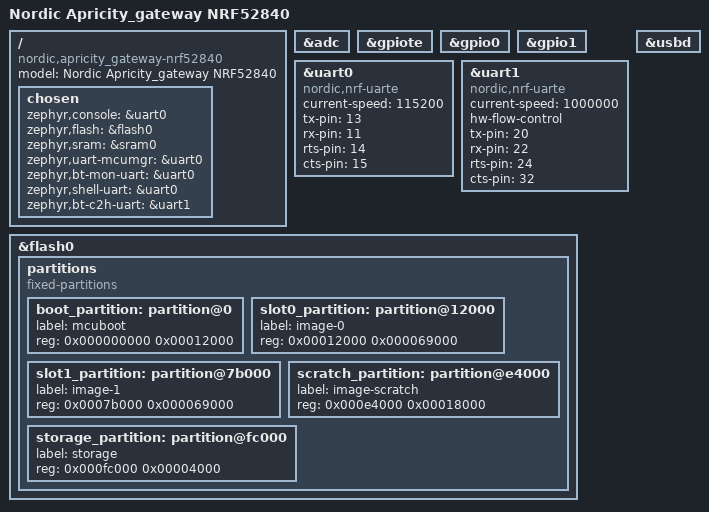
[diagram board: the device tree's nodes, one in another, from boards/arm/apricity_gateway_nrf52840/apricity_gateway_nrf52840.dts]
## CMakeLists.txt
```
#
# Copyright (c) 2018 Nordic Semiconductor
#
# SPDX-License-Identifier: LicenseRef-BSD-5-Clause-Nordic
#

cmake_minimum_required(VERSION 3.13.1)

list(APPEND mcuboot_OVERLAY_CONFIG
  "${CMAKE_CURRENT_SOURCE_DIR}/mcuboot_overlay-rsa.conf"
  )

set(mcuboot_CONF_FILE ${CMAKE_CURRENT_LIST_DIR}/mcuboot.conf)

#set(mcuboot_DTC_OVERLAY_FILE ${CMAKE_CURRENT_LIST_DIR}/apricity_gateway_nrf52840.overlay)

set(BOARD_ROOT ${CMAKE_CURRENT_LIST_DIR})
find_package(Zephyr REQUIRED HINTS $ENV{ZEPHYR_BASE})
project(lte-gateway-ble)

target_sources(app PRIVATE src/main.c)
target_sources(app PRIVATE src/usb_uart_bridge.c)
zephyr_include_directories(src)
```

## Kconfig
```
#
# Copyright (c) 2020 Nordic Semiconductor ASA
#
# SPDX-License-Identifier: LicenseRef-BSD-5-Clause-Nordic
#

menu "LTE Gateway BLE"
endmenu

menu "Zephyr Kernel"
source "Kconfig.zephyr"
endmenu

module = LTE_GATEWAY_BLE
module-str = LTE Gateway BLE
source "${ZEPHYR_BASE}/subsys/logging/Kconfig.template.log_config"
```

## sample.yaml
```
sample:
  description: USB-UART bridge with HCI UART sample
  name: USB-UART bridge HCI
tests:
  test_build:
    build_only: true
    build_on_all: true
    platform_whitelist: nrf52840_pca20035
    tags: ci_build
```

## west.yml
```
manifest:
  remotes:
    - name: nrfcloud
      url-base: https://github.com/nRFCloud
    - name: nordic
      url-base: https://github.com/nrfconnect
    - name: origin
      url-base: https://github.com/plskeggs
  projects:
    - name: sdk-nrf
      path: nrf
      remote: nordic
      revision: main
      import: true
  self:
    path: lte-gateway-ble
```

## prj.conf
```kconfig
#General
CONFIG_REBOOT=y
CONFIG_HEAP_MEM_POOL_SIZE=16384
CONFIG_GPIO=y
CONFIG_POLL=y
CONFIG_BOOTLOADER_MCUBOOT=y

 # USB
CONFIG_USB=y
CONFIG_USB_DEVICE_STACK=y
CONFIG_USB_DEVICE_MANUFACTURER="Apricity"
CONFIG_USB_DEVICE_PRODUCT="Apricity Gateway"
CONFIG_USB_DEVICE_VID=0x1915
CONFIG_USB_DEVICE_PID=0x520F
CONFIG_USB_DEVICE_SN="PCA20035 12PLACEHLDRS"
CONFIG_USB_COMPOSITE_DEVICE=y
CONFIG_USB_CDC_ACM=y
CONFIG_USB_CDC_ACM_RINGBUF_SIZE=4096
CONFIG_USB_CDC_ACM_DEVICE_COUNT=2
CONFIG_USB_CDC_ACM_LOG_LEVEL_INF=y

# Logging
CONFIG_LOG=y
CONFIG_LOG_MODE_IMMEDIATE=n
CONFIG_LOG_BACKEND_FORMAT_TIMESTAMP=n
CONFIG_LOG_DEFAULT_LEVEL=3
CONFIG_LTE_GATEWAY_BLE_LOG_LEVEL_INF=y
CONFIG_USE_SEGGER_RTT=y
CONFIG_SHELL_BACKEND_RTT=n
CONFIG_LOG_BACKEND_RTT=y
CONFIG_LOG_BACKEND_RTT_MODE_DROP=y
CONFIG_LOG_BACKEND_UART=n
CONFIG_SEGGER_RTT_BUFFER_SIZE_UP=256
CONFIG_LOG_PRINTK=y
CONFIG_LOG_PRINTK_MAX_STRING_LENGTH=256
CONFIG_LOG_BUFFER_SIZE=4096
CONFIG_LOG_BACKEND_RTT_MESSAGE_SIZE=256

 # UART
CONFIG_SERIAL=y
CONFIG_UART_INTERRUPT_DRIVEN=y
CONFIG_UART_LINE_CTRL=y
CONFIG_UART_ASYNC_API=n

#BT
CONFIG_BT=y
CONFIG_BT_WAIT_NOP=y
CONFIG_BT_HCI_RAW=y
CONFIG_BT_HCI_RAW_H4=y
CONFIG_BT_HCI_RAW_H4_ENABLE=y
CONFIG_BT_MAX_CONN=16
CONFIG_BT_TINYCRYPT_ECC=n
CONFIG_BT_CTLR_ASSERT_HANDLER=y
CONFIG_BT_HCI_TX_STACK_SIZE=2048
CONFIG_BT_HCI_TX_STACK_SIZE_WITH_PROMPT=y
CONFIG_BT_EXT_ADV=n

CONFIG_BT_DEBUG_LOG=n
CONFIG_BT_DEBUG_CONN=n
CONFIG_BT_DEBUG_HCI_CORE=n
CONFIG_BT_DEBUG_HCI_DRIVER=n
CONFIG_BT_LOG_LEVEL_INF=n
CONFIG_BT_HCI_VS_EXT=n
CONFIG_BT_HCI_VS=n

CONFIG_BT_LL_SOFTDEVICE=y
CONFIG_BT_LL_SW_SPLIT=y

#Reset pin
CONFIG_BOARD_APRICITY_GATEWAY_NRF52840_RESET=y
CONFIG_BOOTLOADER_MCUBOOT=y

# TODO: get this to work
#CONFIG_MCUBOOT_SERIAL=y
#CONFIG_BOOT_SERIAL_DETECT_PORT=0
#CONFIG_BOOT_SERIAL_DETECT_PIN=12

CONFIG_GPIO=y
CONFIG_MAIN_STACK_SIZE=2048
CONFIG_SYSTEM_WORKQUEUE_STACK_SIZE=2048

CONFIG_CLOCK_CONTROL_NRF_K32SRC_20PPM=y
```

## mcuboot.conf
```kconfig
# Note: much of this came from:
# bootloader/mcuboot/boot/zephyr/boards/thingy91_nrf52840.conf

# Disable Zephyr console
CONFIG_LOG=n
CONFIG_CONSOLE=n
CONFIG_CONSOLE_HANDLER=n
CONFIG_UART_CONSOLE=n

# The build won't fit on the partition allocated for it without size
# optimizations.
CONFIG_SIZE_OPTIMIZATIONS=y
CONFIG_PM_PARTITION_SIZE_MCUBOOT=0x12000

#Reset pin
CONFIG_BOARD_APRICITY_GATEWAY_NRF52840_RESET=y

# Serial
CONFIG_SERIAL=y
CONFIG_UART_NRFX=y
CONFIG_UART_INTERRUPT_DRIVEN=y
CONFIG_UART_LINE_CTRL=y

# MCUboot serial recovery
CONFIG_GPIO=y
CONFIG_MCUBOOT_SERIAL=y
CONFIG_BOOT_SERIAL_CDC_ACM=y
CONFIG_BOOT_SERIAL_DETECT_PORT="GPIO_0"
CONFIG_BOOT_SERIAL_DETECT_PIN=12
CONFIG_BOOT_SERIAL_DETECT_PIN_VAL=0

# Required by USB
CONFIG_MULTITHREADING=y

# USB
CONFIG_USB=y
CONFIG_USB_DEVICE_STACK=y
CONFIG_USB_DEVICE_PRODUCT="MCUBOOT"
CONFIG_USB_CDC_ACM=y
CONFIG_USB_COMPOSITE_DEVICE=y
CONFIG_USB_MASS_STORAGE=n
CONFIG_USB_DEVICE_MANUFACTURER="Nordic Semiconductor"
CONFIG_USB_DEVICE_VID=0x1915
CONFIG_USB_DEVICE_PID=0x520F

CONFIG_REBOOT=y
CONFIG_FLASH=y
CONFIG_MAIN_STACK_SIZE=10240
CONFIG_PARTITION_MANAGER_ENABLED=y
CONFIG_FPROTECT=y
CONFIG_HW_STACK_PROTECTION=y
```

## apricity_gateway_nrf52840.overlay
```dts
/* SPDX-License-Identifier: Apache-2.0 */

/ {
	chosen {
	};
};

/* This overlay is for MCUBOOT, used if needed to deviate from the
	application's device tree */
```

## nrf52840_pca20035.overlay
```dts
/* SPDX-License-Identifier: Apache-2.0 */

/ {
	chosen {
		zephyr,bt-c2h-uart=&uart1;
	};
};

// &uart1 {
// 	compatible = "nordic,nrf-uarte";
// 	current-speed = <1000000>;
// 	status = "okay";
//         tx-pin = <0x19>;
//         rx-pin = <0x20>;
//         rts-pin = <0x16>;
//         cts-pin = <0x13>;
// };


&uart0 {
	compatible = "nordic,nrf-uarte";
	current-speed = <0x1c200>;
	status = "okay";
	tx-pin = < 0x0d >;
	rx-pin = < 0x0b >;
	rts-pin = < 0x0e >;
	cts-pin = < 0x0f >;
};


&uart1 {
	compatible = "nordic,nrf-uarte";
	current-speed = <0xf4240>;
	status = "okay";
	tx-pin = < 0x14 >;
	rx-pin = < 0x16 >;
	rts-pin = < 0x18 >;
	cts-pin = < 0x20 >;
};
```

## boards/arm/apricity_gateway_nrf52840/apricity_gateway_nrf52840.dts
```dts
/*
 * Copyright (c) 2020 Nordic Semiconductor ASA
 *
 * SPDX-License-Identifier: LicenseRef-BSD-5-Clause-Nordic
 */

/dts-v1/;
#include <nordic/nrf52840_qiaa.dtsi>

/ {
	model = "Nordic Apricity_gateway NRF52840";
	compatible = "nordic,apricity_gateway-nrf52840";

	chosen {
		zephyr,console = &uart0;
		zephyr,flash = &flash0;
		zephyr,sram = &sram0;
		zephyr,uart-mcumgr = &uart0;
		zephyr,bt-mon-uart = &uart0;
		zephyr,shell-uart = &uart0;
		zephyr,bt-c2h-uart = &uart1;
	};
};

&adc {
	status = "okay";
};

&gpiote {
	status = "okay";
};

&gpio0 {
	status = "okay";
};

&gpio1 {
	status = "okay";
};

&uart0 {
	compatible = "nordic,nrf-uarte";
	current-speed = <115200>;
	status = "okay";
	tx-pin = < 13 >;
	rx-pin = < 11 >;
	rts-pin = < 14 >;
	cts-pin = < 15 >;
};

&uart1 {
	compatible = "nordic,nrf-uarte";
	current-speed = <1000000>;
	status = "okay";
	hw-flow-control;
	tx-pin = < 20 >;
	rx-pin = < 22 >;
	rts-pin = < 24 >;
	cts-pin = < 32 >;
};

&usbd {
	status = "okay";
};

&flash0 {
	partitions {
		compatible = "fixed-partitions";
		#address-cells = <1>;
		#size-cells = <1>;

		/* The size of this partition ensures that MCUBoot can be built
		 * with an RTT console, CDC ACM support, and w/o optimizations.
		 */
		boot_partition: partition@0 {
			label = "mcuboot";
			reg = <0x000000000 0x00012000>;
		};
		slot0_partition: partition@12000 {
			label = "image-0";
			reg = <0x00012000 0x000069000>;
		};
		slot1_partition: partition@7b000 {
			label = "image-1";
			reg = <0x0007b000 0x000069000>;
		};
		scratch_partition: partition@e4000 {
			label = "image-scratch";
			reg = <0x000e4000 0x00018000>;
		};
		storage_partition: partition@fc000 {
			label = "storage";
			reg = <0x000fc000 0x00004000>;
		};
	};
};
```

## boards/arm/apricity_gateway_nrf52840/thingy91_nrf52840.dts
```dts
/*
 * Copyright (c) 2019 Nordic Semiconductor ASA
 *
 * SPDX-License-Identifier: LicenseRef-BSD-5-Clause-Nordic
 */

/dts-v1/;
#include <nordic/nrf52840_qiaa.dtsi>

/ {
	model = "Nordic Thingy91 NRF52840";
	compatible = "nordic,thingy91-nrf52840";

	chosen {
		zephyr,console = &uart0;
		zephyr,flash = &flash0;
		zephyr,sram = &sram0;
		zephyr,uart-mcumgr = &uart0;
		zephyr,bt-mon-uart = &uart0;
		zephyr,shell-uart = &uart0;
	};
};

&adc {
	status = "okay";
};

&gpiote {
	status = "okay";
};

&gpio0 {
	status = "okay";
};

&gpio1 {
	status = "okay";
};

//&uart0 {
//	compatible = "nordic,nrf-uarte";
//	current-speed = <115200>;
//	status = "okay";
//	tx-pin = <15>;
//	rx-pin = <11>;
//	rts-pin = <21>;
//	cts-pin = <20>;
//};

&uart0 {
	compatible = "nordic,nrf-uarte";
	current-speed = <115200>;
	status = "okay";
	tx-pin = <28>;
	rx-pin = <30>;
};

&uart1 {
	current-speed = <1000000>;
	status = "okay";
	tx-pin = <25>;
	rx-pin = <32>;
	rts-pin = <22>;
	cts-pin = <19>;
};

&usbd {
	status = "okay";
};

&flash0 {
	partitions {
		compatible = "fixed-partitions";
		#address-cells = <1>;
		#size-cells = <1>;

		/* The size of this partition ensures that MCUBoot can be built
		 * with an RTT console, CDC ACM support, and w/o optimizations.
		 */
		boot_partition: partition@0 {
			label = "mcuboot";
			reg = <0x000000000 0x00012000>;
		};
		slot0_partition: partition@12000 {
			label = "image-0";
			reg = <0x00012000 0x000069000>;
		};
		slot1_partition: partition@7b000 {
			label = "image-1";
			reg = <0x0007b000 0x000069000>;
		};
		scratch_partition: partition@e4000 {
			label = "image-scratch";
			reg = <0x000e4000 0x00018000>;
		};
		storage_partition: partition@fc000 {
			label = "storage";
			reg = <0x000fc000 0x00004000>;
		};
	};
};
```

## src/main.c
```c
/*
 * Copyright (c) 2016-2021 Nordic Semiconductor ASA
 * Copyright (c) 2015-2016 Intel Corporation
 *
 * SPDX-License-Identifier: Apache-2.0
 */
#include <errno.h>
#include <stddef.h>
#include <stdio.h>
#include <string.h>

#include <zephyr.h>
#include <arch/cpu.h>
#include <sys/byteorder.h>
#include <logging/log.h>
#include <sys/util.h>

#include <device.h>
#include <init.h>
#include <drivers/uart.h>

#include <net/buf.h>
#include <bluetooth/bluetooth.h>
#include <bluetooth/l2cap.h>
#include <bluetooth/hci.h>
#include <bluetooth/buf.h>
#include <bluetooth/hci_raw.h>

#include <nrfx.h>
#include <hal/nrf_power.h>
#include <power/reboot.h>
#include <usb/usb_device.h>
#include <drivers/gpio.h>

#include "usb_uart_bridge.h"

LOG_MODULE_REGISTER(lte_gateway_ble, CONFIG_LTE_GATEWAY_BLE_LOG_LEVEL);

static const struct device *hci_uart_dev =
	DEVICE_DT_GET(DT_CHOSEN(zephyr_bt_c2h_uart));
static K_THREAD_STACK_DEFINE(tx_thread_stack, CONFIG_BT_HCI_TX_STACK_SIZE);
static struct k_thread tx_thread_data;
static K_FIFO_DEFINE(tx_queue);

/* RX in terms of bluetooth communication */
static K_FIFO_DEFINE(uart_tx_queue);

/* build for < rev3 hardware -- the BLE LED control used to be managed by
 * the 52840, but in newer boards is controlled by the 9160
 */
/* #define OLD_BOARD */

#if 0
/* HCI command buffers */
NET_BUF_POOL_FIXED_DEFINE(acl_tx_pool, TX_BUF_COUNT, BT_BUF_ACL_SIZE, NULL);
NET_BUF_POOL_FIXED_DEFINE(cmd_tx_pool, CONFIG_BT_HCI_CMD_COUNT, CMD_BUF_SIZE,
			  NULL);

/* #define DEBUG_UART_PINS */
#if defined(DEBUG_UART_PINS)
#define UART0 DT_NODELABEL(uart0)
#define UART0_TX DT_PROP(UART0, tx_pin)
#define UART0_RX DT_PROP(UART0, rx_pin)
#define UART0_RTS DT_PROP(UART0, rts_pin)
#define UART0_CTS DT_PROP(UART0, cts_pin)
#define UART0_SPEED DT_PROP(UART0, current_speed)
#define UART1 DT_NODELABEL(uart1)
#define UART1_TX DT_PROP(UART1, tx_pin)
#define UART1_RX DT_PROP(UART1, rx_pin)
#define UART1_RTS DT_PROP(UART1, rts_pin)
#define UART1_CTS DT_PROP(UART1, cts_pin)
#define UART1_SPEED DT_PROP(UART1, current_speed)
#endif

#if defined(CONFIG_BT_CTLR_TX_BUFFER_SIZE)
#define BT_L2CAP_MTU (CONFIG_BT_CTLR_TX_BUFFER_SIZE - BT_L2CAP_HDR_SIZE)
#else
#define BT_L2CAP_MTU 65 /* 64-byte public key + opcode */
#endif /* CONFIG_BT_CTLR */

/** Data size needed for ACL buffers */
#define BT_BUF_ACL_SIZE BT_L2CAP_BUF_SIZE(BT_L2CAP_MTU)

#if defined(CONFIG_BT_CTLR_TX_BUFFERS)
#define TX_BUF_COUNT CONFIG_BT_CTLR_TX_BUFFERS
#else
#define TX_BUF_COUNT 6
#endif
#define CMD_BUF_SIZE BT_BUF_RX_SIZE
#endif

#define H4_CMD 0x01
#define H4_ACL 0x02
#define H4_SCO 0x03
#define H4_EVT 0x04

/* Receiver states. */
#define ST_IDLE 0	/* Waiting for packet type. */
#define ST_HDR 1	/* Receiving packet header. */
#define ST_PAYLOAD 2	/* Receiving packet payload. */
#define ST_DISCARD 3	/* Dropping packet. */

/* Length of a discard/flush buffer.
 * This is sized to align with a BLE HCI packet:
 * 1 byte H:4 header + 32 bytes ACL/event data
 * Bigger values might overflow the stack since this is declared as a local
 * variable, smaller ones will force the caller to call into discard more
 * often.
 */
#define H4_DISCARD_LEN 33

#define H4_SEND_TIMEOUT 5000

static int h4_read(const struct device *uart, uint8_t *buf, size_t len)
{
	int rx = uart_fifo_read(uart, buf, len);

	LOG_DBG("read %d req %d", rx, len);

	return rx;
}

static bool valid_type(uint8_t type)
{
	return (type == H4_CMD) || (type == H4_ACL);
}

/* Function assumes that type is validated and only CMD or ACL will be used. */
static uint32_t get_len(const uint8_t *hdr_buf, uint8_t type)
{
	return (type == BT_BUF_CMD) ?
		((const struct bt_hci_cmd_hdr *)hdr_buf)->param_len :
		sys_le16_to_cpu(((const struct bt_hci_acl_hdr *)hdr_buf)->len);
}

/* Function assumes that type is validated and only CMD or ACL will be used. */
static int hdr_len(uint8_t type)
{
	return (type == H4_CMD) ?
		sizeof(struct bt_hci_cmd_hdr) : sizeof(struct bt_hci_acl_hdr);
}

static void rx_isr(void)
{
	static struct net_buf *buf;
	static int remaining;
	static uint8_t state;
	static uint8_t type;
	static uint8_t hdr_buf[MAX(sizeof(struct bt_hci_cmd_hdr),
			sizeof(struct bt_hci_acl_hdr))];
	int read;

	do {
		switch (state) {
		case ST_IDLE:
			/* Get packet type */
			read = h4_read(hci_uart_dev, &type, sizeof(type));
			/* since we read in loop until no data is in the fifo,
			 * it is possible that read = 0.
			 */
			if (read) {
				if (valid_type(type)) {
					/* Get expected header size and switch
					 * to receiving header.
					 */
					remaining = hdr_len(type);
					state = ST_HDR;
				} else {
					LOG_WRN("Unknown header %d", type);
				}
			}
			break;
		case ST_HDR:
			read = h4_read(hci_uart_dev,
				       &hdr_buf[hdr_len(type) - remaining],
				       remaining);
			remaining -= read;
			if (remaining == 0) {
				/* Header received. Allocate buffer and get
				 * payload length. If allocation fails leave
				 * interrupt. On failed allocation state machine
				 * is reset.
				 */
				buf = bt_buf_get_tx(BT_BUF_H4, K_NO_WAIT,
						    &type, sizeof(type));
				if (!buf) {
					state = ST_IDLE;
					return;
				}

				remaining = get_len(hdr_buf, type);

				net_buf_add_mem(buf, hdr_buf, hdr_len(type));
				if (remaining > net_buf_tailroom(buf)) {
					LOG_ERR("Not enough space in buffer");
					net_buf_unref(buf);
					state = ST_DISCARD;
				} else {
					state = ST_PAYLOAD;
				}

			}
			break;
		case ST_PAYLOAD:
			read = h4_read(hci_uart_dev, net_buf_tail(buf),
				       remaining);
			buf->len += read;
			remaining -= read;
			if (remaining == 0) {
				/* Packet received */
				LOG_DBG("putting RX packet in queue.");
				net_buf_put(&tx_queue, buf);
				state = ST_IDLE;
			}
			break;
		case ST_DISCARD:
		{
			uint8_t discard[H4_DISCARD_LEN];
			size_t to_read = MIN(remaining, sizeof(discard));

			read = h4_read(hci_uart_dev, discard, to_read);
			remaining -= read;
			if (remaining == 0) {
				state = ST_IDLE;
			}

			break;

		}
		default:
			read = 0;
			__ASSERT_NO_MSG(0);
			break;

		}
	} while (read);
}

static void tx_isr(void)
{
	static struct net_buf *buf;
	int len;

	if (!buf) {
		buf = net_buf_get(&uart_tx_queue, K_NO_WAIT);
		if (!buf) {
			uart_irq_tx_disable(hci_uart_dev);
			return;
		}
	}

	len = uart_fifo_fill(hci_uart_dev, buf->data, buf->len);
	net_buf_pull(buf, len);
	if (!buf->len) {
		net_buf_unref(buf);
		buf = NULL;
	}
}

static void bt_uart_isr(const struct device *unused, void *user_data)
{
	ARG_UNUSED(unused);
	ARG_UNUSED(user_data);

	if (!(uart_irq_rx_ready(hci_uart_dev) ||
	      uart_irq_tx_ready(hci_uart_dev))) {
		LOG_DBG("spurious interrupt");
	}

	if (uart_irq_tx_ready(hci_uart_dev)) {
		tx_isr();
	}

	if (uart_irq_rx_ready(hci_uart_dev)) {
		rx_isr();
	}
}

static void tx_thread(void *p1, void *p2, void *p3)
{
	while (1) {
		struct net_buf *buf;
		int err;

		/* Wait until a buffer is available */
		buf = net_buf_get(&tx_queue, K_FOREVER);
		/* Pass buffer to the stack */
		LOG_HEXDUMP_DBG(buf->data, buf->len, "tx_thread");
		LOG_DBG("net_buf_get() returned len %d", buf->len);
		err = bt_send(buf);
		if (err) {
			LOG_ERR("Unable to send (err %d)", err);
			net_buf_unref(buf);
		}

		/* Give other threads a chance to run if tx_queue keeps getting
		 * new data all the time.
		 */
		k_yield();
	}
}

static int h4_send(struct net_buf *buf)
{
	LOG_DBG("buf %p type %u len %u", buf, bt_buf_get_type(buf),
		    buf->len);

	net_buf_put(&uart_tx_queue, buf);
	uart_irq_tx_enable(hci_uart_dev);

	return 0;
}

#if defined(CONFIG_BT_CTLR_ASSERT_HANDLER)
void bt_ctlr_assert_handle(char *file, uint32_t line)
{
	uint32_t len = 0U, pos = 0U;

	/* Disable interrupts, this is unrecoverable */
	(void)irq_lock();

	uart_irq_rx_disable(hci_uart_dev);
	uart_irq_tx_disable(hci_uart_dev);

	if (file) {
		while (file[len] != '\0') {
			if (file[len] == '/') {
				pos = len + 1;
			}
			len++;
		}
		file += pos;
		len -= pos;
	}

	uart_poll_out(hci_uart_dev, H4_EVT);
	/* Vendor-Specific debug event */
	uart_poll_out(hci_uart_dev, 0xff);
	/* 0xAA + strlen + \0 + 32-bit line number */
	uart_poll_out(hci_uart_dev, 1 + len + 1 + 4);
	uart_poll_out(hci_uart_dev, 0xAA);

	if (len) {
		while (*file != '\0') {
			uart_poll_out(hci_uart_dev, *file);
			file++;
		}
		uart_poll_out(hci_uart_dev, 0x00);
	}

	uart_poll_out(hci_uart_dev, line >> 0 & 0xff);
	uart_poll_out(hci_uart_dev, line >> 8 & 0xff);
	uart_poll_out(hci_uart_dev, line >> 16 & 0xff);
	uart_poll_out(hci_uart_dev, line >> 24 & 0xff);

	while (1) {
	}
}
#endif /* CONFIG_BT_CTLR_ASSERT_HANDLER */

static int hci_uart_init(const struct device *unused)
{
	LOG_DBG("init hci uart");

	if (!device_is_ready(hci_uart_dev)) {
		LOG_ERR("HCI UART %s is not ready", hci_uart_dev->name);
		return -EINVAL;
	}

	uart_irq_rx_disable(hci_uart_dev);
	uart_irq_tx_disable(hci_uart_dev);

	uart_irq_callback_set(hci_uart_dev, bt_uart_isr);

	uart_irq_rx_enable(hci_uart_dev);

	return 0;
}

SYS_DEVICE_DEFINE("hci_uart", hci_uart_init, NULL,
		  APPLICATION, CONFIG_KERNEL_INIT_PRIORITY_DEVICE);

#if defined(OLD_BOARD)
void set_leds(bool red, bool green, bool blue)
{
	const struct device *port;
	int red_pin = 26;
	int green_pin = 4;
	int blue_pin = 6;
	int err;

	port = device_get_binding(DT_LABEL(DT_NODELABEL(gpio0)));
	if (!port) {
		LOG_INF("GPIO0 device not found!");
	} else {
		err = gpio_pin_configure(port, red_pin,
			red ? GPIO_OUTPUT_LOW : GPIO_OUTPUT_HIGH);
		if (err) {
			LOG_INF("Pin %d error %d", red_pin, err);
		}
		err = gpio_pin_configure(port, green_pin,
			green ? GPIO_OUTPUT_LOW : GPIO_OUTPUT_HIGH);
		if (err) {
			LOG_INF("Pin %d error %d", green_pin, err);
		}
		err = gpio_pin_configure(port, blue_pin,
			blue ? GPIO_OUTPUT_LOW : GPIO_OUTPUT_HIGH);
		if (err) {
			LOG_INF("Pin %d error %d", blue_pin, err);
		}
	}
}
#endif

void output_string(int id, char *str)
{
	struct serial_dev *sd = &devs[id];
	struct uart_data *rx = k_malloc(sizeof(struct uart_data));

	if (rx) {
		memset(rx, 0, sizeof(rx));
		rx->len = strlen(str);
		strcpy(rx->buffer, str);
		k_fifo_put(sd->fifo, rx);
		k_sem_give(&sd->sem);
	}
}

#define DBG(x) output_string(0, x)

static void log_uart_pins(void)
{
#if defined(DEBUG_UART_PINS)
	struct uart_config config;
	struct device *uart_0_dev = device_get_binding("UART_0");
	struct device *uart_1_dev = device_get_binding("UART_1");

	LOG_INF("UART0 tx:%d, rx:%d, rts:%d, cts:%d, speed:%d",
		UART0_TX, UART0_RX, UART0_RTS, UART0_CTS, UART0_SPEED);
	LOG_INF("UART1 tx:%d, rx:%d, rts:%d, cts:%d, speed:%d",
		UART1_TX, UART1_RX, UART1_RTS, UART1_CTS, UART1_SPEED);
	k_sleep(K_MSEC(50));

	uart_config_get(uart_0_dev, &config);
	LOG_INF("UART0 speed:%u, flow:%d", config.baudrate,
		config.flow_ctrl);
	k_sleep(K_MSEC(50));

	uart_config_get(uart_1_dev, &config);
	LOG_INF("UART1 speed:%u, flow:%d", config.baudrate,
		config.flow_ctrl);

	LOG_INF("Reset pin:%d",
		CONFIG_BOARD_APRICITY_GATEWAY_NRF52840_RESET_PIN);
#endif
}

extern bool ignore_reset;
void main(void)
{
	ignore_reset = false;

	/* incoming events and data from the controller */
	static K_FIFO_DEFINE(rx_queue);
	int err;
	int ret;
	struct serial_dev *usb_0_sd = &devs[0];
	struct serial_dev *uart_0_sd = &devs[1];
	const struct device *usb_0_dev;
	const struct device *uart_0_dev;

#if defined(OLD_BOARD)
	set_leds(true, false, false);
#endif
	__ASSERT(hci_uart_dev, "UART device is NULL");

	/* Enable the raw interface, this will in turn open the HCI driver */
	bt_enable_raw(&rx_queue);
#if defined(OLD_BOARD)
	set_leds(false, true, false);
#endif
	LOG_INF("LTE Gateway BLE started");
	log_uart_pins();

	if (IS_ENABLED(CONFIG_BT_WAIT_NOP)) {
		/* Issue a Command Complete with NOP */
		int i;

		const struct {
			const uint8_t h4;
			const struct bt_hci_evt_hdr hdr;
			const struct bt_hci_evt_cmd_complete cc;
		} __packed cc_evt = {
			.h4 = H4_EVT,
			.hdr = {
				.evt = BT_HCI_EVT_CMD_COMPLETE,
				.len = sizeof(struct bt_hci_evt_cmd_complete),
			},
			.cc = {
				.ncmd = 1,
				.opcode = sys_cpu_to_le16(BT_OP_NOP),
			},
		};

		LOG_INF("Sending HCI Cmd Complete w/ NOP");
		for (i = 0; i < sizeof(cc_evt); i++) {
			uart_poll_out(hci_uart_dev,
				      *(((const uint8_t *)&cc_evt)+i));
		}
	}

	/* Spawn the TX thread and start feeding commands and data to the
	 * controller
	 */
	k_thread_create(&tx_thread_data, tx_thread_stack,
			K_THREAD_STACK_SIZEOF(tx_thread_stack), tx_thread,
			NULL, NULL, NULL, K_PRIO_COOP(7), 0, K_NO_WAIT);
	k_thread_name_set(&tx_thread_data, "HCI uart TX");

	usb_0_dev = device_get_binding("CDC_ACM_0");
	if (!usb_0_dev) {
		LOG_INF("CDC ACM device not found");
		return;
	}

	uart_0_dev = device_get_binding("UART_0");
	if (!uart_0_dev) {
		LOG_INF("UART 0 init failed");
	}

	usb_0_sd->num = -1;
	usb_0_sd->dev = usb_0_dev;
	usb_0_sd->fifo = &usb_0_tx_fifo;
	usb_0_sd->peer = uart_0_sd;

	uart_0_sd->num = 0;
	uart_0_sd->dev = uart_0_dev;
	uart_0_sd->fifo = &uart_0_tx_fifo;
	uart_0_sd->peer = usb_0_sd;

	k_sem_init(&usb_0_sd->sem, 0, 1);
	k_sem_init(&uart_0_sd->sem, 0, 1);

	uart_bridge_init(usb_0_sd, uart_0_sd);

	uart_irq_callback_user_data_set(usb_0_dev, uart_interrupt_handler,
		usb_0_sd);
	uart_irq_callback_user_data_set(uart_0_dev, uart_interrupt_handler,
		uart_0_sd);

	ret = usb_enable(NULL);
	if (ret != 0) {
		LOG_INF("Failed to enable USB");
		return;
	}

	uart_irq_rx_enable(usb_0_dev);
	uart_irq_rx_enable(uart_0_dev);

	struct k_poll_event events[2] = {
		K_POLL_EVENT_STATIC_INITIALIZER(K_POLL_TYPE_SEM_AVAILABLE,
						K_POLL_MODE_NOTIFY_ONLY,
						&usb_0_sd->sem, 0),
		K_POLL_EVENT_STATIC_INITIALIZER(K_POLL_TYPE_SEM_AVAILABLE,
						K_POLL_MODE_NOTIFY_ONLY,
						&uart_0_sd->sem, 0),
	};

	LOG_INF("Entering loop");
#if defined(OLD_BOARD)
	set_leds(false, false, true);
#endif

	while (1) {
		struct net_buf *buf;

		buf = net_buf_get(&rx_queue, K_NO_WAIT);
		if (buf) {
			err = h4_send(buf);
			if (err) {
				LOG_ERR("Failed to send");
#if defined(OLD_BOARD)
				set_leds(true, false, false);
#endif
			} else {
#if defined(OLD_BOARD)
				set_leds(false, true, false);
#endif
			}
		}
		ret = k_poll(events, ARRAY_SIZE(events), K_NO_WAIT);
		if (ret != 0) {
			k_sleep(K_MSEC(1));
#if defined(OLD_BOARD)
			set_leds(false, false, true);
#endif
			continue;
		}

		if (events[0].state == K_POLL_TYPE_SEM_AVAILABLE) {
			events[0].state = K_POLL_STATE_NOT_READY;
			k_sem_take(&usb_0_sd->sem, K_NO_WAIT);
#if defined(OLD_BOARD)
			set_leds(false, true, true);
#endif
			LOG_DBG("en usb0 tx");
			uart_irq_tx_enable(usb_0_dev);
		} else if (events[1].state == K_POLL_TYPE_SEM_AVAILABLE) {
			events[1].state = K_POLL_STATE_NOT_READY;
			k_sem_take(&uart_0_sd->sem, K_NO_WAIT);
#if defined(OLD_BOARD)
			set_leds(true, false, true);
#endif
			LOG_DBG("en uart0 tx");
			uart_irq_tx_enable(uart_0_dev);
		}
	}
}
```

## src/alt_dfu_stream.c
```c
#include "alt_dfu_stream.h"

#include "tk_mqtt_dfu.h"

#include "cJSON.h"

#include <kernel.h>

#include <stdbool.h>
#include <stdio.h>
#include <stdlib.h>
#include <string.h>


/* Copied from dfu_target_peripheral.h */
#define DFU_PACKET_MAGIC_LEN (8u)
#define DFU_MAGIC_STRING "XoPU24Tk"

#define DFU_PACKET_HEADER_LEN (DFU_PACKET_MAGIC_LEN + 6u)
#define DFU_HEADER_FMT (DFU_MAGIC_STRING " %04d %s\n")

#define DFU_MAX_CHUNK_LEN (128u)

#define DFU_JSON_MAX_B64_DATA_LEN (4u * (DFU_MAX_CHUNK_LEN / 3u) + 3u)
#define DFU_JSON_MAX_LEN (DFU_JSON_MAX_B64_DATA_LEN + 100u)

#define DFU_PACKET_MAX_BUFFER_LEN \
	(DFU_PACKET_HEADER_LEN + DFU_JSON_MAX_LEN + 2u)

#define TX_PACKET_MAX_BUFFER_LEN (200u)

#define CMD_START_DFU   (7u)
#define CMD_DFU_DATA    (9u)


/* Local buffers */
K_MUTEX_DEFINE(rx_buffer_mutex);
static uint8_t rx_buffer[DFU_PACKET_MAX_BUFFER_LEN];
static volatile size_t rx_buffer_len = 0;

static char resp_str[(TX_PACKET_MAX_BUFFER_LEN - DFU_PACKET_HEADER_LEN) + 1];
static uint8_t tx_buffer[TX_PACKET_MAX_BUFFER_LEN];
static size_t tx_buffer_len = 0;


static inline void trim_rx_buffer(size_t idx)
{
	k_mutex_lock(&rx_buffer_mutex, K_FOREVER);

	if (idx >= rx_buffer_len) {
		rx_buffer_len = 0u;
	} else if (idx > 0) {
		rx_buffer_len = rx_buffer_len - idx;
		memmove(rx_buffer, rx_buffer+idx, rx_buffer_len);
	}

	k_mutex_unlock(&rx_buffer_mutex);
}

static void build_response_pkt(cJSON * response)
{
	int olen = 0;

	if ((NULL != response) &&
		cJSON_PrintPreallocated(response, resp_str, sizeof(resp_str), false)) {
		size_t json_len = strlen(resp_str);
		olen = snprintf((char *) tx_buffer, sizeof(tx_buffer),
						DFU_HEADER_FMT, json_len, resp_str);
	} else {
		int olen = snprintf((char *) tx_buffer, sizeof(tx_buffer),
							DFU_HEADER_FMT, 2, "{}");
	}

	if (olen < sizeof(tx_buffer)) {
		tx_buffer_len = olen;
	} else {
		tx_buffer_len = 0;
	}
}

static void process_rx_pkt(const char *json_str)
{
	cJSON *obj = cJSON_Parse(json_str);
	cJSON *response = NULL;

	if (NULL != obj) {
		cJSON * cmd_obj = cJSON_GetObjectItem(obj, "cmd");
		if ((NULL != cmd_obj) && cJSON_IsNumber(cmd_obj)) {
			switch(cmd_obj->valueint)
			{
			case CMD_START_DFU:
				response = TK_MQTT_DFU_START_M(obj);
				break;
			case CMD_DFU_DATA:
				response = TK_MQTT_DFU_DATA_M(obj);
				break;
			default:
				break;
			}
		}
	}

	build_response_pkt(response);
	cJSON_Delete(response);
	cJSON_Delete(obj);
}

static void process_rx_buffer(void)
{
	do
	{
		if (rx_buffer_len < DFU_PACKET_HEADER_LEN) {
			/* Not enough data to process*/
			break;
		}

		/* Trim off any garbage in the buffer */
		size_t trim_idx = 0;
		for (; trim_idx < (rx_buffer_len - DFU_PACKET_MAGIC_LEN); ++trim_idx) {
			if (DFU_MAGIC_STRING[0] == rx_buffer[trim_idx]) {
				break;
			}
		}
		if (trim_idx > 0) {
			trim_rx_buffer(trim_idx);
			continue;
		}

		if (0 != memcmp(rx_buffer, DFU_MAGIC_STRING, DFU_PACKET_MAGIC_LEN)) {
			/* Magic string does not match, remove the garbage */
			trim_rx_buffer(1);
			continue;
		}

		/* Grab the length field */
		size_t json_len = 0u;
		{
			char len_str[5];
			memcpy(len_str, &rx_buffer[DFU_PACKET_MAGIC_LEN + 1], 4);
			len_str[4] = '\0';

			long int raw_len = strtol(len_str, NULL, 10);
			if ((0 == raw_len) || (raw_len > DFU_JSON_MAX_LEN)) {
				/* Invalid length field, thrown the mysteriously matching magic
				   string */
				trim_rx_buffer(DFU_PACKET_MAGIC_LEN);
				continue;
			}
			json_len = (size_t) raw_len;
		}

		size_t pkt_len = json_len + DFU_PACKET_HEADER_LEN;
		if (rx_buffer_len < pkt_len) {
			/* Not enough bytes to extract the JSON data */
			break;
		}

		const char *json_str = (const char *) &rx_buffer[DFU_PACKET_HEADER_LEN];
		rx_buffer[pkt_len] = '\0';

		/* Complete packet has been received, process it. We will break
		   from the loop here so that a response message can be sent back */
		process_rx_pkt(json_str);
		trim_rx_buffer(pkt_len);
	} while(0);
}

void alt_dfu_process(void)
{
	if (tx_buffer_len == 0) {
		/* Only process data if there isn't an outgoing packet */
		process_rx_buffer();
	}
}

void alt_dfu_receive(const uint8_t *data, size_t len)
{
	k_mutex_lock(&rx_buffer_mutex, K_FOREVER);

	size_t to_copy = len;
	size_t bytes_free = sizeof(rx_buffer) - rx_buffer_len;
	if (bytes_free < len)
		to_copy = bytes_free;

	memcpy(&rx_buffer[rx_buffer_len], data, to_copy);
	rx_buffer_len += to_copy;

	k_mutex_unlock(&rx_buffer_mutex);
}

bool alt_dfu_is_tx_pending(void)
{
	return (tx_buffer_len > 0);
}

const uint8_t *alt_dfu_get_pending_tx(size_t *len)
{
	if (tx_buffer_len > 0) {
		*len = tx_buffer_len;
		tx_buffer_len = 0;
		return tx_buffer;
	} else {
		*len = 0;
		return NULL;
	}
}
```

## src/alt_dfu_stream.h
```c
#ifndef ALT_DFU_STREAM_H_
#define ALT_DFU_STREAM_H_

#include <stdbool.h>
#include <stdint.h>
#include <stddef.h>

void alt_dfu_process(void);

void alt_dfu_receive(const uint8_t *data, size_t len);

bool alt_dfu_is_tx_pending(void);

const uint8_t *alt_dfu_get_pending_tx(size_t *len);

#endif /* ALT_DFU_STREAM_H_ */
```

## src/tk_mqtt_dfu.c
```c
#include "tk_mqtt_dfu.h"

#include "tk_shutdown.h"

#include <cJSON.h>
#include <cJSON_os.h>

#include <zephyr.h>
#include <logging/log.h>

#include <dfu/flash_img.h>
#include <dfu/mcuboot.h>
#include <power/reboot.h>
#include <sys/base64.h>

#include <string.h>

LOG_MODULE_REGISTER(alt_dfu_stream, CONFIG_LTE_GATEWAY_BLE_LOG_LEVEL);

#define MAX_DATA_LENGTH         2048            // 2048*4/3 = size of base64 string of 2048

#define FILE_SIZE_NAME          "file_size"
#define MAX_CHUNK_NAME          "max_chunk_size"
#define VERSION_NAME            "version"
#define TOTAL_MSQ_COUNT_NAME    "total_msg_count"
#define MSG_ID_NAME             "msg_id"
#define CHUNK_NAME              "chunk_size"
#define DATA_NAME               "data"
#define DEV_ID_NAME             "devID"

static int file_size = 0;
static int max_chunk_size = 0;
static int final_msg = 0;
static int current_msg = 0;

static struct	flash_img_context flash_img;


static cJSON * tk_mqtt_create_request(void);


// static char version[] = "00.00.00" // Not currently using version

// Process a message to start a DFU process
/*
{
    "cmd":CMD_START_DFU,
    "file_size":250000,     // bytes
    "max_chunk_size":2048,  // bytes
    "version":"1.0.0",      // string
    "total_msg_count":245   // Number of messages expected
}
*/
cJSON * tk_mqtt_dfu_start(cJSON *msg){

    int err = flash_img_init(&flash_img);

	if (err != 0) {
		LOG_ERR("flash_img_init error %d", err);
		return NULL;
	}

    current_msg = 0;

    cJSON *fs = cJSON_GetObjectItem(msg,FILE_SIZE_NAME);
    if(fs == NULL)
    {
        LOG_ERR("Missing File Size");
        return NULL;
    }
    file_size = fs->valueint;

    cJSON *mcs = cJSON_GetObjectItem(msg,MAX_CHUNK_NAME);
    if(mcs == NULL)
    {
        LOG_ERR("Missing Chunk Size");
        return NULL;
    }
    max_chunk_size = mcs->valueint;

    cJSON *tmc =  cJSON_GetObjectItem(msg,TOTAL_MSQ_COUNT_NAME);
    if(tmc == NULL)
    {
        LOG_ERR("Missing Total Message Count");
        return NULL;
    }
    final_msg = tmc->valueint - 1;

    // Send request for first message
    return tk_mqtt_create_request();
}


// Process a dfu data message
/*
{
    "cmd":CMD_DFU_DATA,
    "msg_id":145,               // ID of the message
    "chunk_size":2048,          // bytes
    "data":"BASE64ENCODEDDATA"  //String
}
*/
static uint16_t msg_id = 0;
static size_t chunk_size = 0;
static uint8_t data[MAX_DATA_LENGTH];
static size_t olen;
cJSON * tk_mqtt_dfu_data(cJSON *msg){

    int err;

    cJSON *mi = cJSON_GetObjectItem(msg, MSG_ID_NAME);
    msg_id = mi->valueint;

    LOG_INF("msg_id %d, current_id %d", msg_id, current_msg);
    if(msg_id != current_msg)
    {
        return NULL;
    }
    else if ((current_msg-msg_id) == 1)
    {
        //If we received a previous message again, then the central server probably failed to get this
        //request, so send it again.
        return tk_mqtt_create_request();
    }

    cJSON *cs = cJSON_GetObjectItem(msg, CHUNK_NAME);
    chunk_size = cs->valueint;

    // Get data string and decode to uint8_t
    cJSON *d = cJSON_GetObjectItem(msg, DATA_NAME);
    base64_decode(data,chunk_size,&olen,d->valuestring,strlen(d->valuestring));

    LOG_INF("Chunk size:%d, Olen:%d",chunk_size,olen);

    // Write to flash
    err = flash_img_buffered_write(&flash_img,data,olen, false);
    if (err != 0) {
        LOG_ERR("flash_img_buffered_write error %d", err);
        return NULL;
    }

    // If last message
    if(msg_id == final_msg){
		/* Write with 0 length to flush the write operation to flash. */
		err = flash_img_buffered_write(&flash_img, data, 0, true);
		if (err != 0) {
			LOG_ERR("flash_img_buffered_write error %d", err);
			return NULL;
		}
        current_msg = -1;   // -1 is indication of final message received
        tk_mqtt_create_request(); // send back completion message
        k_sleep(K_MSEC(1000));          // to make sure final message response gets out before we reboot
        // Request boot upgrade
		err = boot_request_upgrade(1);
		if (err != 0) {
			LOG_ERR("boot_request_upgrade error %d", err);
			return NULL;
		}

        // Completed upgrade, rebooting
        LOG_ERR("Completed upgrade, rebooting");
        TK_SHUTDOWN_M();

    }else{
        current_msg = current_msg+1;
        return tk_mqtt_create_request();
    }
    return NULL;
}



// Create and send data request message
/*
{
    "devID":"A00004",
    "msg_id":234        // Send a request for message id
}
*/
static cJSON * tk_mqtt_create_request(void){
    cJSON *obj = cJSON_CreateObject();

    if ((NULL == obj)
        || (NULL == cJSON_AddStringToObject(obj, DEV_ID_NAME, "undefined"))
        || (NULL == cJSON_AddNumberToObject(obj, MSG_ID_NAME, current_msg))) {

        cJSON_Delete(obj);
        return NULL;
    }

    return obj;
}
```

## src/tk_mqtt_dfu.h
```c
#ifndef TK_MQTT_DFU_H
#define TK_MQTT_DFU_H

#include "cJSON.h"

#define TK_MQTT_DFU_START_M(message_json)               tk_mqtt_dfu_start(message_json)
#define TK_MQTT_DFU_DATA_M(message_json)                tk_mqtt_dfu_data(message_json)

cJSON * tk_mqtt_dfu_start(cJSON *msg);
cJSON * tk_mqtt_dfu_data(cJSON *msg);


#endif // TK_MQTT_DFU_H
```

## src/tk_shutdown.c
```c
#include <power/reboot.h>
#include "tk_shutdown.h"
// #include "app_energy.h"
// #include "app_mqtt.h"
// TODO: Renable and handle shutdown properly
void tk_shutdown(void)
{
    // APP_ENERGY_SHUTDOWN_M();
    // APP_MQTT_DISCONNECT_M();
    sys_reboot(0);
}
```

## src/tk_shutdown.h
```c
#ifndef TK_SHUTDOWN_H
#define TK_SHUTDOWN_H

#define TK_SHUTDOWN_M()             tk_shutdown()


void tk_shutdown(void);



#endif
```

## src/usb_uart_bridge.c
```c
/*
 * Copyright (c) 2019 Nordic Semiconductor ASA
 *
 * SPDX-License-Identifier: LicenseRef-BSD-5-Clause-Nordic
 */

#include <zephyr.h>
#include <device.h>
#include <drivers/uart.h>
#include <nrfx.h>
#include <string.h>
#include <stdio.h>
#include <hal/nrf_power.h>
#include <power/reboot.h>
#include <usb/usb_device.h>
#include <logging/log.h>
#include <logging/log_ctrl.h>

#include "usb_uart_bridge.h"

#define UART_IRQ_TX_EMPTY_LOOP_COUNT 1000000
/* #define LOG_CONTENTS */

LOG_MODULE_REGISTER(usb_uart_bridge, CONFIG_LTE_GATEWAY_BLE_LOG_LEVEL);

/* Overriding weak function to set iSerial runtime. */
uint8_t *usb_update_sn_string_descriptor(void)
{
	static uint8_t buf[] = "NRFBLEGW_12PLACEHLDRS";

	snprintk(&buf[9], 13, "%04X%08X",
		(uint32_t)(NRF_FICR->DEVICEADDR[1] & 0x0000FFFF)|0x0000C000,
		(uint32_t)NRF_FICR->DEVICEADDR[0]);

	return (uint8_t *)&buf;
}



/* Frees data for incoming transmission on device blocked by full heap. */
static int oom_free(struct serial_dev *sd)
{
	struct serial_dev *peer_sd = (struct serial_dev *)sd->peer;
	struct uart_data *buf;

	/* First, try to free from FIFO of peer device (blocked stream) */
	buf = k_fifo_get(peer_sd->fifo, K_NO_WAIT);
	if (buf) {
		k_free(buf);
		return 0;
	}

	/* Then, try FIFO of the receiving device (reverse of blocked stream) */
	buf = k_fifo_get(sd->fifo, K_NO_WAIT);
	if (buf) {
		k_free(buf);
		return 0;
	}

	/* Finally, try all of them */
	for (int i = 0; i < ARRAY_SIZE(devs); i++) {
		buf = k_fifo_get(sd->fifo, K_NO_WAIT);
		if (buf) {
			k_free(buf);
			return 0;
		}
	}

	return -1; /* Was not able to free any heap memory */
}

void uart_timer_handler(struct k_timer *timer_id)
{
	void *user_data = k_timer_user_data_get(timer_id);
	struct serial_dev *sd = user_data;
	struct serial_dev *peer_sd = (struct serial_dev *)sd->peer;
	struct uart_data *rx;

	rx = sd->rx;
	sd->rx = NULL;
	if (rx) {
		k_fifo_put(peer_sd->fifo, rx);
		k_sem_give(&peer_sd->sem);
	} else  {
		LOG_DBG("timer ignored");
	}

}

void uart_bridge_init(struct serial_dev *sd0, struct serial_dev *sd1)
{
	k_timer_init(&sd0->timer, uart_timer_handler, NULL);
	k_timer_init(&sd1->timer, uart_timer_handler, NULL);
}

void uart_interrupt_handler(const struct device *dev, void *user_data)
{
	struct serial_dev *sd = user_data;
	struct serial_dev *peer_sd = (struct serial_dev *)sd->peer;
	struct uart_data *rx;
#if defined(LOG_CONTENTS)
	static char rxlabel[32];
	static char txlabel[32];
#endif

	uart_irq_update(dev);

	while (uart_irq_rx_ready(dev)) {
		int data_length;

		while (!sd->rx) {
			sd->rx = k_malloc(sizeof(*sd->rx));
			if (sd->rx) {
				sd->rx->len = 0;
			} else {
				int err = oom_free(sd);

				if (err) {
					LOG_ERR("Could not free memory."
						" Rebooting.");
					sys_reboot(SYS_REBOOT_COLD);
				}
			}
		}

		data_length = uart_fifo_read(dev, &sd->rx->buffer[sd->rx->len],
					   UART_BUF_SIZE - sd->rx->len);
		sd->rx->len += data_length;

		if (sd->rx->len > 0) {
			if ((sd->rx->len == UART_BUF_SIZE) ||
			   (sd->rx->buffer[sd->rx->len - 1] == '\n') ||
			   (sd->rx->buffer[sd->rx->len - 1] == '\r') ||
			   (sd->rx->buffer[sd->rx->len - 1] == '\0')) {
#if defined(LOG_CONTENTS)
				sprintf(rxlabel, "uart_fifo_rx %d", sd->num);
				LOG_HEXDUMP_DBG(sd->rx->buffer,
					sd->rx->len, rxlabel);
#else
				LOG_DBG("rx%d-%d RCVD", sd->num, sd->rx->len);
#endif
				k_timer_stop(&sd->timer);
				rx = sd->rx;
				sd->rx = NULL;
				k_fifo_put(peer_sd->fifo, rx);
				k_sem_give(&peer_sd->sem);
			} else if (!k_timer_remaining_ticks(&sd->timer)) {
				k_timer_user_data_set(&sd->timer, user_data);
				k_timer_start(&sd->timer, K_MSEC(50),
					      K_NO_WAIT);
			}
		}
	}

	if (uart_irq_tx_ready(dev)) {
		struct uart_data *buf = k_fifo_get(sd->fifo, K_NO_WAIT);
		uint16_t written = 0;

		/* Nothing in the FIFO, nothing to send */
		if (!buf) {
			uart_irq_tx_disable(dev);
			return;
		}

#if defined(LOG_CONTENTS)
		if (buf->len) {
			sprintf(txlabel, "uart_fifo_tx %d", sd->num);
			LOG_HEXDUMP_DBG(buf->buffer, buf->len,
				txlabel);
		}
#else
		if (buf->len) {
			LOG_DBG("tx%d-%d SENT", sd->num, buf->len);
		}
#endif

		while (buf->len > written) {
			if (uart_irq_tx_ready(dev)) {
				written += uart_fifo_fill(dev,
							  &buf->buffer[written],
							  buf->len - written);
			}
		}

		int i = 0;

		while (!uart_irq_tx_complete(dev)) {
			/* Wait for the last byte to get
			 * shifted out of the module
			 */
			if (i++ > UART_IRQ_TX_EMPTY_LOOP_COUNT) {
				LOG_ERR("timeout on tx complete");
				break;
			}
		}

		if (k_fifo_is_empty(sd->fifo)) {
			uart_irq_tx_disable(dev);
		}

		k_free(buf);
	}
}

void power_thread(void)
{
	while (1) {
		if (!nrf_power_usbregstatus_vbusdet_get(NRF_POWER)) {
			nrf_power_system_off(NRF_POWER);
		}
		k_sleep(K_MSEC(100));
	}
}

K_THREAD_DEFINE(power_thread_id, POWER_THREAD_STACKSIZE, power_thread,
		NULL, NULL, NULL, POWER_THREAD_PRIORITY, 0, 0);
```

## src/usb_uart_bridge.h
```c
#ifndef _USB_UART_BRIDGE_H_
#define _USB_UART_BRIDGE_H_

#define POWER_THREAD_STACKSIZE		CONFIG_IDLE_STACK_SIZE
#define POWER_THREAD_PRIORITY		K_LOWEST_APPLICATION_THREAD_PRIO

/* Heap block space is always one of 2^(2n) for n from 3 to 7.
 * (see reference/kernel/memory/heap.html for more info)
 * Here, we target 64-byte blocks. Since we want to fit one struct uart_data
 * into each block, the block layout becomes:
 * 16 bytes: reserved by the Zephyr heap block descriptor (not in struct)
 *  4 bytes: reserved by the Zephyr FIFO (in struct)
 * 40 bytes: UART data buffer (in struct)
 *  4 bytes: length field (in struct, padded for alignment)
 */
#define UART_BUF_SIZE 40

static K_FIFO_DEFINE(usb_0_tx_fifo);
static K_FIFO_DEFINE(uart_0_tx_fifo);

struct uart_data {
	void *fifo_reserved;
	uint8_t buffer[UART_BUF_SIZE];
	uint16_t len;
};

struct uart_alt_stream {
	void (*receive)(const uint8_t *data, size_t len);
};

static struct serial_dev {
	struct k_timer timer;
	const struct device *dev;
	void *peer;
	struct k_fifo *fifo;
	struct k_sem sem;
	struct uart_data *rx;
	int num;
	struct uart_alt_stream *alt_stream;
} devs[2];

void uart_bridge_init(struct serial_dev *sd0, struct serial_dev *sd1);
void uart_interrupt_handler(const struct device *dev, void *user_data);
void power_thread(void);

#endif
```
